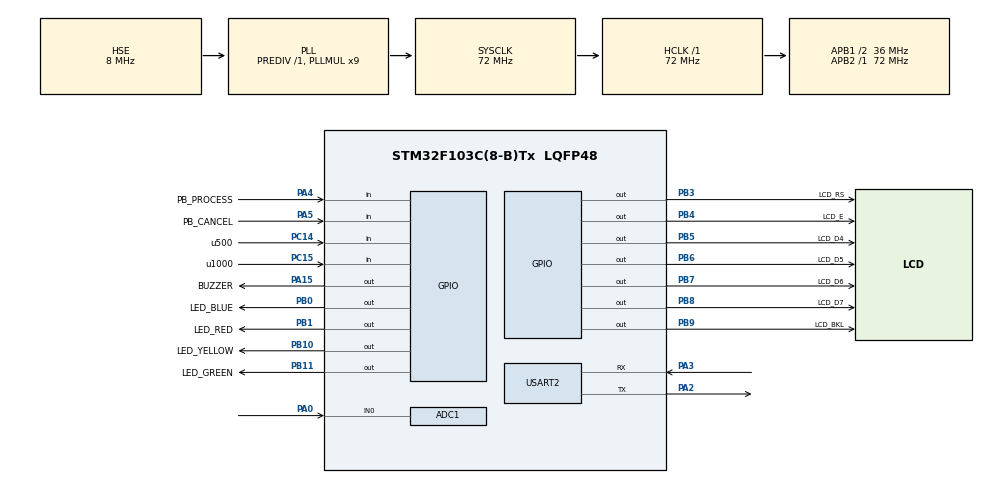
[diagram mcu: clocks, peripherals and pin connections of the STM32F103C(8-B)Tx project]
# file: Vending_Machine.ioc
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ADC1.Channel-0\#ChannelRegularConversion=ADC_CHANNEL_0
ADC1.NbrOfConversionFlag=1
ADC1.Rank-0\#ChannelRegularConversion=1
ADC1.SamplingTime-0\#ChannelRegularConversion=ADC_SAMPLETIME_1CYCLE_5
ADC1.master=1
Mcu.Family=STM32F1
Mcu.Name=STM32F103C(8-B)Tx
Mcu.Package=LQFP48
NVIC.PriorityGroup=NVIC_PRIORITYGROUP_4
NVIC.TIM2_IRQn=true\:0\:0\:false\:false\:true\:true\:true
PA0-WKUP.Signal=ADCx_IN0
PA13.Mode=Serial_Wire
PA13.Signal=SYS_JTMS-SWDIO
PA14.Mode=Serial_Wire
PA14.Signal=SYS_JTCK-SWCLK
PA15.GPIO_Label=BUZZER
PA15.Signal=GPIO_Output
PA2.Mode=Asynchronous
PA2.Signal=USART2_TX
PA3.Mode=Asynchronous
PA3.Signal=USART2_RX
PA4.GPIO_Label=PB_PROCESS
PA4.GPIO_PuPd=GPIO_PULLUP
PA4.Signal=GPIO_Input
PA5.GPIO_Label=PB_CANCEL
PA5.GPIO_PuPd=GPIO_PULLUP
PA5.Signal=GPIO_Input
PB0.GPIO_Label=LED_BLUE
PB0.Signal=GPIO_Output
PB1.GPIO_Label=LED_RED
PB1.Signal=GPIO_Output
PB10.GPIO_Label=LED_YELLOW
PB10.Signal=GPIO_Output
PB11.GPIO_Label=LED_GREEN
PB11.Signal=GPIO_Output
PB3.GPIO_Label=LCD_RS
PB3.Signal=GPIO_Output
PB4.GPIO_Label=LCD_E
PB4.Signal=GPIO_Output
PB5.GPIO_Label=LCD_D4
PB5.Signal=GPIO_Output
PB6.GPIO_Label=LCD_D5
PB6.Signal=GPIO_Output
PB7.GPIO_Label=LCD_D6
PB7.Signal=GPIO_Output
PB8.GPIO_Label=LCD_D7
PB8.Signal=GPIO_Output
PB9.GPIO_Label=LCD_BKL
PB9.Signal=GPIO_Output
PC14-OSC32_IN.GPIO_Label=u500
PC14-OSC32_IN.GPIO_PuPd=GPIO_PULLUP
PC14-OSC32_IN.Signal=GPIO_Input
PC15-OSC32_OUT.GPIO_Label=u1000
PC15-OSC32_OUT.GPIO_PuPd=GPIO_PULLUP
PC15-OSC32_OUT.Signal=GPIO_Input
PD0-OSC_IN.Mode=HSE-External-Oscillator
PD0-OSC_IN.Signal=RCC_OSC_IN
PD1-OSC_OUT.Mode=HSE-External-Oscillator
PD1-OSC_OUT.Signal=RCC_OSC_OUT
ProjectManager.HeapSize=0x200
ProjectManager.StackSize=0x400
ProjectManager.TargetToolchain=STM32CubeIDE
RCC.ADCPresc=RCC_ADCPCLK2_DIV6
RCC.AHBFreq_Value=72000000
RCC.APB1CLKDivider=RCC_HCLK_DIV2
RCC.APB1Freq_Value=36000000
RCC.APB1TimFreq_Value=72000000
RCC.APB2Freq_Value=72000000
RCC.APB2TimFreq_Value=72000000
RCC.HCLKFreq_Value=72000000
RCC.PLLMUL=RCC_PLL_MUL9
RCC.PLLSourceVirtual=RCC_PLLSOURCE_HSE
RCC.SYSCLKFreq_VALUE=72000000
RCC.SYSCLKSource=RCC_SYSCLKSOURCE_PLLCLK
RCC.USBFreq_Value=72000000
SH.ADCx_IN0.0=ADC1_IN0,IN0
TIM2.Period=3
TIM2.Prescaler=35999
USART2.VirtualMode=VM_ASYNC
VP_TIM2_VS_ClockSourceINT.Mode=Internal
board=custom

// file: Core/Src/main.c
/* USER CODE BEGIN Header */
/**
  ******************************************************************************
  * @file           : main.c
  * @brief          : Main program body
  ******************************************************************************
  * @attention
  *
  * <h2><center>&copy; Copyright (c) 2019 STMicroelectronics.
  * All rights reserved.</center></h2>
  *
  * This software component is licensed by ST under BSD 3-Clause license,
  * the "License"; You may not use this file except in compliance with the
  * License. You may obtain a copy of the License at:
  *                        opensource.org/licenses/BSD-3-Clause
  *
  ******************************************************************************
  */
/* USER CODE END Header */

#include "main.h"

/* USER CODE BEGIN Includes */
#include "myLCD.h"
#include "myTask.h"
/* USER CODE END Includes */

ADC_HandleTypeDef hadc1;

TIM_HandleTypeDef htim2;

UART_HandleTypeDef huart2;

void SystemClock_Config(void);
static void MX_GPIO_Init(void);
static void MX_ADC1_Init(void);
static void MX_USART2_UART_Init(void);
static void MX_TIM2_Init(void);

int main(void)
{

  /* MCU Configuration--------------------------------------------------------*/

  /* Reset of all peripherals, Initializes the Flash interface and the Systick. */
  HAL_Init();

  /* Configure the system clock */
  SystemClock_Config();

  /* Initialize all configured peripherals */
  MX_GPIO_Init();
  MX_ADC1_Init();
  MX_USART2_UART_Init();
  MX_TIM2_Init();
  /* USER CODE BEGIN 2 */
  myTask_init();
  HAL_TIM_Base_Start_IT(&htim2);

  /* USER CODE END 2 */

  /* Infinite loop */
  while (1)
  {

  }
}

void SystemClock_Config(void)
{
  RCC_OscInitTypeDef RCC_OscInitStruct = {0};
  RCC_ClkInitTypeDef RCC_ClkInitStruct = {0};
  RCC_PeriphCLKInitTypeDef PeriphClkInit = {0};

  /** Initializes the CPU, AHB and APB busses clocks
  */
  RCC_OscInitStruct.OscillatorType = RCC_OSCILLATORTYPE_HSE;
  RCC_OscInitStruct.HSEState = RCC_HSE_ON;
  RCC_OscInitStruct.HSEPredivValue = RCC_HSE_PREDIV_DIV1;
  RCC_OscInitStruct.HSIState = RCC_HSI_ON;
  RCC_OscInitStruct.PLL.PLLState = RCC_PLL_ON;
  RCC_OscInitStruct.PLL.PLLSource = RCC_PLLSOURCE_HSE;
  RCC_OscInitStruct.PLL.PLLMUL = RCC_PLL_MUL9;
  if (HAL_RCC_OscConfig(&RCC_OscInitStruct) != HAL_OK)
  {
    Error_Handler();
  }
  /** Initializes the CPU, AHB and APB busses clocks
  */
  RCC_ClkInitStruct.ClockType = RCC_CLOCKTYPE_HCLK|RCC_CLOCKTYPE_SYSCLK
                              |RCC_CLOCKTYPE_PCLK1|RCC_CLOCKTYPE_PCLK2;
  RCC_ClkInitStruct.SYSCLKSource = RCC_SYSCLKSOURCE_PLLCLK;
  RCC_ClkInitStruct.AHBCLKDivider = RCC_SYSCLK_DIV1;
  RCC_ClkInitStruct.APB1CLKDivider = RCC_HCLK_DIV2;
  RCC_ClkInitStruct.APB2CLKDivider = RCC_HCLK_DIV1;

  if (HAL_RCC_ClockConfig(&RCC_ClkInitStruct, FLASH_LATENCY_2) != HAL_OK)
  {
    Error_Handler();
  }
  PeriphClkInit.PeriphClockSelection = RCC_PERIPHCLK_ADC;
  PeriphClkInit.AdcClockSelection = RCC_ADCPCLK2_DIV6;
  if (HAL_RCCEx_PeriphCLKConfig(&PeriphClkInit) != HAL_OK)
  {
    Error_Handler();
  }
}

static void MX_ADC1_Init(void)
{

  ADC_ChannelConfTypeDef sConfig = {0};

  /** Common config
  */
  hadc1.Instance = ADC1;
  hadc1.Init.ScanConvMode = ADC_SCAN_DISABLE;
  hadc1.Init.ContinuousConvMode = DISABLE;
  hadc1.Init.DiscontinuousConvMode = DISABLE;
  hadc1.Init.ExternalTrigConv = ADC_SOFTWARE_START;
  hadc1.Init.DataAlign = ADC_DATAALIGN_RIGHT;
  hadc1.Init.NbrOfConversion = 1;
  if (HAL_ADC_Init(&hadc1) != HAL_OK)
  {
    Error_Handler();
  }
  /** Configure Regular Channel
  */
  sConfig.Channel = ADC_CHANNEL_0;
  sConfig.Rank = ADC_REGULAR_RANK_1;
  sConfig.SamplingTime = ADC_SAMPLETIME_1CYCLE_5;
  if (HAL_ADC_ConfigChannel(&hadc1, &sConfig) != HAL_OK)
  {
    Error_Handler();
  }

}

static void MX_TIM2_Init(void)
{

  TIM_ClockConfigTypeDef sClockSourceConfig = {0};
  TIM_MasterConfigTypeDef sMasterConfig = {0};

  htim2.Instance = TIM2;
  htim2.Init.Prescaler = 35999;
  htim2.Init.CounterMode = TIM_COUNTERMODE_UP;
  htim2.Init.Period = 3;
  htim2.Init.ClockDivision = TIM_CLOCKDIVISION_DIV1;
  htim2.Init.AutoReloadPreload = TIM_AUTORELOAD_PRELOAD_DISABLE;
  if (HAL_TIM_Base_Init(&htim2) != HAL_OK)
  {
    Error_Handler();
  }
  sClockSourceConfig.ClockSource = TIM_CLOCKSOURCE_INTERNAL;
  if (HAL_TIM_ConfigClockSource(&htim2, &sClockSourceConfig) != HAL_OK)
  {
    Error_Handler();
  }
  sMasterConfig.MasterOutputTrigger = TIM_TRGO_RESET;
  sMasterConfig.MasterSlaveMode = TIM_MASTERSLAVEMODE_DISABLE;
  if (HAL_TIMEx_MasterConfigSynchronization(&htim2, &sMasterConfig) != HAL_OK)
  {
    Error_Handler();
  }

}

static void MX_USART2_UART_Init(void)
{

  huart2.Instance = USART2;
  huart2.Init.BaudRate = 115200;
  huart2.Init.WordLength = UART_WORDLENGTH_8B;
  huart2.Init.StopBits = UART_STOPBITS_1;
  huart2.Init.Parity = UART_PARITY_NONE;
  huart2.Init.Mode = UART_MODE_TX_RX;
  huart2.Init.HwFlowCtl = UART_HWCONTROL_NONE;
  huart2.Init.OverSampling = UART_OVERSAMPLING_16;
  if (HAL_UART_Init(&huart2) != HAL_OK)
  {
    Error_Handler();
  }

}

static void MX_GPIO_Init(void)
{
  GPIO_InitTypeDef GPIO_InitStruct = {0};

  /* GPIO Ports Clock Enable */
  __HAL_RCC_GPIOC_CLK_ENABLE();
  __HAL_RCC_GPIOD_CLK_ENABLE();
  __HAL_RCC_GPIOA_CLK_ENABLE();
  __HAL_RCC_GPIOB_CLK_ENABLE();

  /*Configure GPIO pin Output Level */
  HAL_GPIO_WritePin(GPIOB, LED_BLUE_Pin|LED_RED_Pin|LED_YELLOW_Pin|LED_GREEN_Pin
                          |LCD_RS_Pin|LCD_E_Pin|LCD_D4_Pin|LCD_D5_Pin
                          |LCD_D6_Pin|LCD_D7_Pin|LCD_BKL_Pin, GPIO_PIN_RESET);

  /*Configure GPIO pin Output Level */
  HAL_GPIO_WritePin(BUZZER_GPIO_Port, BUZZER_Pin, GPIO_PIN_RESET);

  /*Configure GPIO pins : u500_Pin u1000_Pin */
  GPIO_InitStruct.Pin = u500_Pin|u1000_Pin;
  GPIO_InitStruct.Mode = GPIO_MODE_INPUT;
  GPIO_InitStruct.Pull = GPIO_PULLUP;
  HAL_GPIO_Init(GPIOC, &GPIO_InitStruct);

  /*Configure GPIO pins : PB_PROCESS_Pin PB_CANCEL_Pin */
  GPIO_InitStruct.Pin = PB_PROCESS_Pin|PB_CANCEL_Pin;
  GPIO_InitStruct.Mode = GPIO_MODE_INPUT;
  GPIO_InitStruct.Pull = GPIO_PULLUP;
  HAL_GPIO_Init(GPIOA, &GPIO_InitStruct);

  /*Configure GPIO pins : LED_BLUE_Pin LED_RED_Pin LED_YELLOW_Pin LED_GREEN_Pin
                           LCD_RS_Pin LCD_E_Pin LCD_D4_Pin LCD_D5_Pin
                           LCD_D6_Pin LCD_D7_Pin LCD_BKL_Pin */
  GPIO_InitStruct.Pin = LED_BLUE_Pin|LED_RED_Pin|LED_YELLOW_Pin|LED_GREEN_Pin
                          |LCD_RS_Pin|LCD_E_Pin|LCD_D4_Pin|LCD_D5_Pin
                          |LCD_D6_Pin|LCD_D7_Pin|LCD_BKL_Pin;
  GPIO_InitStruct.Mode = GPIO_MODE_OUTPUT_PP;
  GPIO_InitStruct.Pull = GPIO_NOPULL;
  GPIO_InitStruct.Speed = GPIO_SPEED_FREQ_LOW;
  HAL_GPIO_Init(GPIOB, &GPIO_InitStruct);

  /*Configure GPIO pin : BUZZER_Pin */
  GPIO_InitStruct.Pin = BUZZER_Pin;
  GPIO_InitStruct.Mode = GPIO_MODE_OUTPUT_PP;
  GPIO_InitStruct.Pull = GPIO_NOPULL;
  GPIO_InitStruct.Speed = GPIO_SPEED_FREQ_LOW;
  HAL_GPIO_Init(BUZZER_GPIO_Port, &GPIO_InitStruct);

}

void Error_Handler(void)
{
}

/************************ (C) COPYRIGHT STMicroelectronics *****END OF FILE****/
